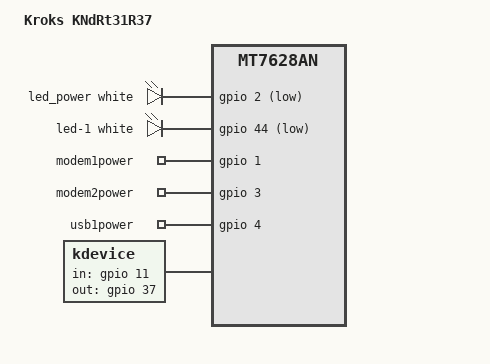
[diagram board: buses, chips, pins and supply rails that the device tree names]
#include "mt7628an_kroks_4reth.dtsi"

#include <dt-bindings/leds/common.h>

/ {
	compatible = "kroks,kndrt31r37", "mediatek,mt7628an-soc";
	model = "Kroks KNdRt31R37";

	aliases {
		led-boot = &led_power;
		led-failsafe = &led_power;
		led-running = &led_power;
		led-upgrade = &led_power;
	};

	leds {
		compatible = "gpio-leds";

		led_power: led-0 {
			function = LED_FUNCTION_POWER;
			color = <LED_COLOR_ID_WHITE>;
			gpios = <&gpio 2 GPIO_ACTIVE_LOW>;
		};

		led-1 {
			function = LED_FUNCTION_WLAN;
			color = <LED_COLOR_ID_WHITE>;
			gpios = <&gpio 44 GPIO_ACTIVE_LOW>;
			linux,default-trigger = "phy0tpt";
		};
	};

	gpio_export {
		compatible = "gpio-export";
		#size-cells = <0>;

		modem1power {
			gpio-export,name = "modem1power";
			gpio-export,output = <1>;
			gpios = <&gpio 1 GPIO_ACTIVE_HIGH>;
		};

		modem2power {
			gpio-export,name = "modem2power";
			gpio-export,output = <1>;
			gpios = <&gpio 3 GPIO_ACTIVE_HIGH>;
		};

		usb1power {
			gpio-export,name = "usb1power";
			gpio-export,output = <1>;
			gpios = <&gpio 4 GPIO_ACTIVE_HIGH>;
		};
	};

	kdevice {
		compatible = "kdevice";

		in-gpios = <&gpio 11 GPIO_ACTIVE_HIGH>;
		out-gpios = <&gpio 37 GPIO_ACTIVE_HIGH>;
	};
};

/* drop lan/wan partition */
&esw {
	/delete-property/ mediatek,portmap;
	/delete-property/ mediatek,portdisable;
};

&state_default {
	gpio {
		groups = "i2s", "i2c", "wled_an";
		function = "gpio";
	};

	gpio_lock {
		groups = "gpio", "refclk";
		function = "gpio";
	};
};
